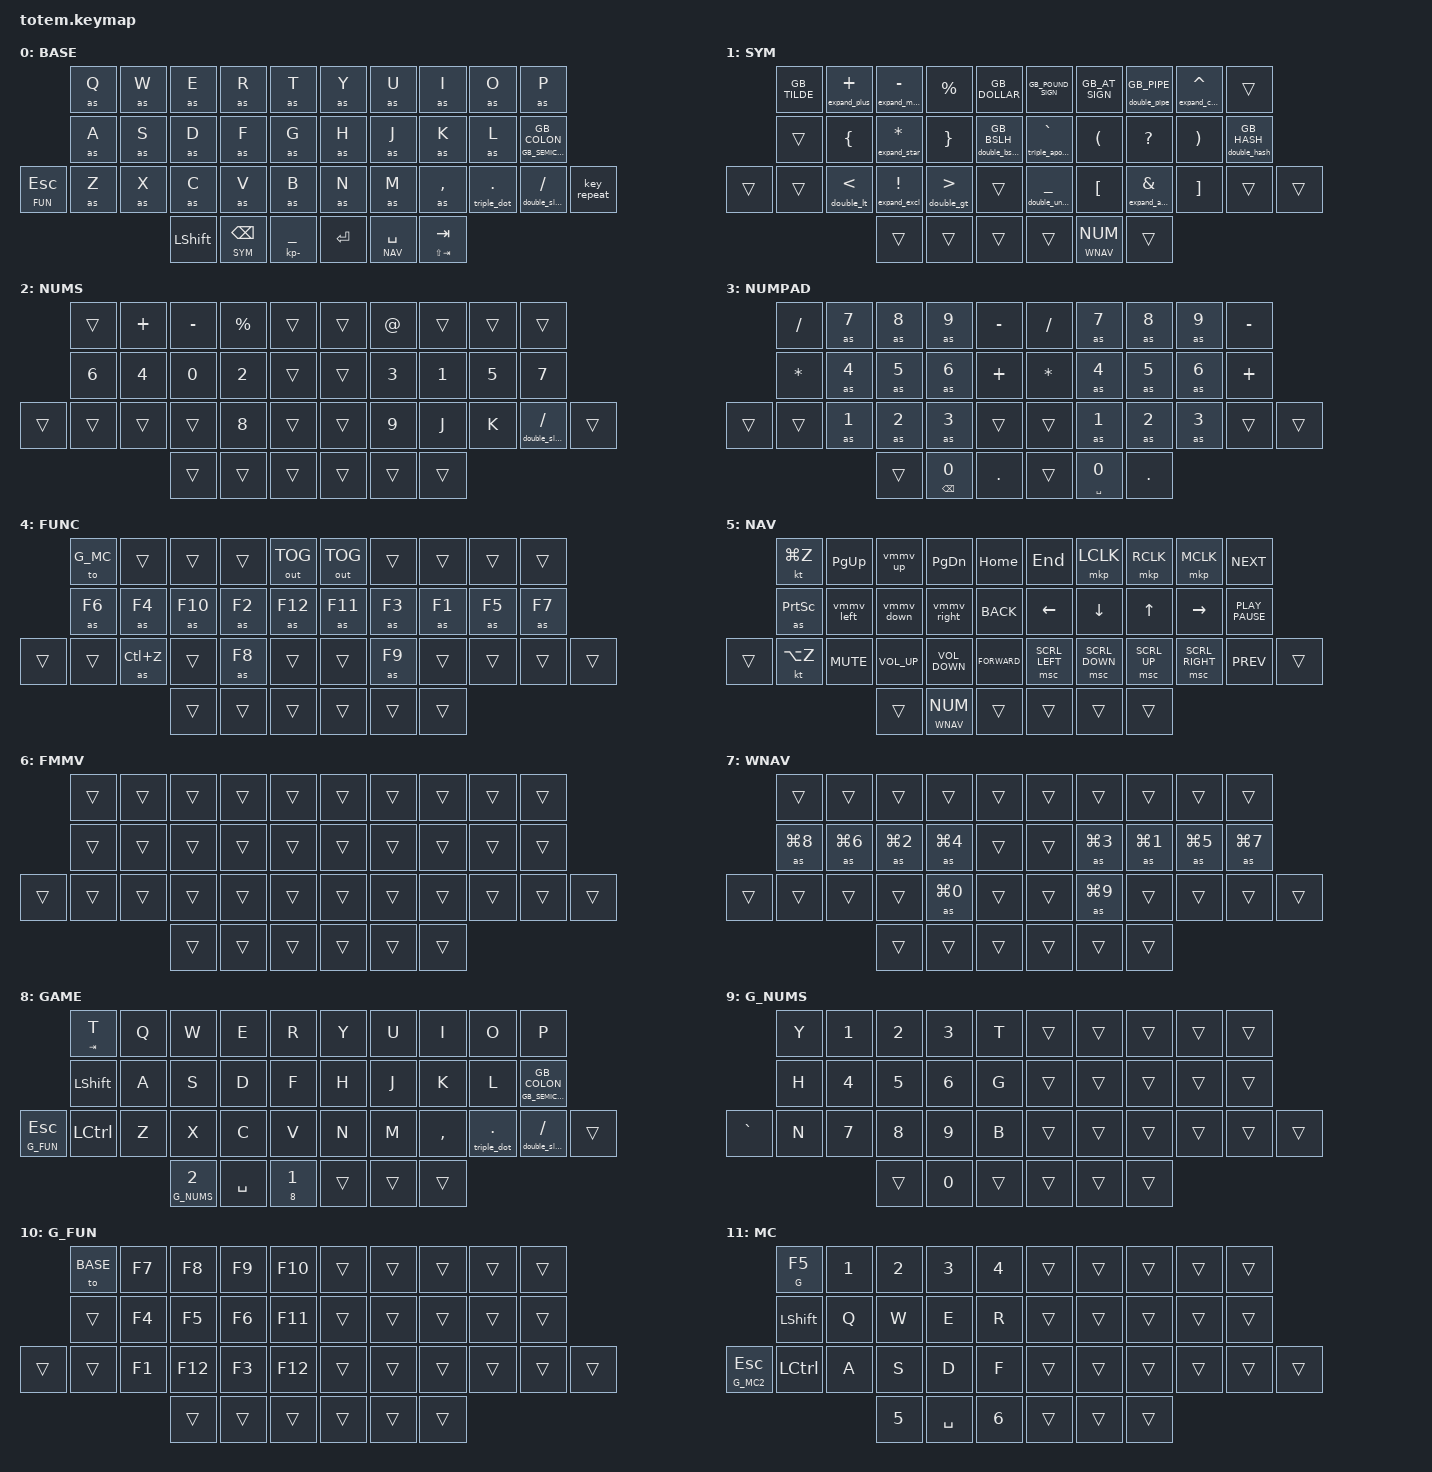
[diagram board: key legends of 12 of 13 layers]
//
//                                                        ▀▀▀▀▀     ▀▀▀▀▀          ▀▀█▀▀
//                                                        ▄▀▀▀▄  ▄  ▄▀▀▀▄  ▄  ▄▀▀▀▄  █  ▄▀▀▀▄
//                                                        █   █  █  █   █  █  █   █  █  █   █
//                                                         ▀▀▀   █   ▀▀▀   █   ▀▀▀   ▀   ▀▀▀
//                                                               █      ▄▄▄█▄▄▄    █   █
//                                                               ▀      █  █  █     █▄█
//                                                             ▀▀▀▀▀    █  █  █      ▀
//                                                                      ▀  ▀  ▀
//
// ▄▄▄▄▄▄▄▄▄▄▄▄▄▄▄▄▄▄▄▄▄▄▄▄▄▄▄▄▄▄▄▄▄▄▄▄▄▄▄▄▄▄▄▄▄▄▄▄▄▄▄▄▄▄▄▄▄▄▄▄▄▄▄▄▄▄▄▄▄▄▄▄▄▄▄▄▄▄▄▄▄▄▄▄▄▄▄▄▄▄▄▄▄▄▄▄▄▄▄▄▄▄▄▄▄▄▄▄▄▄▄▄▄▄▄▄▄▄▄▄▄▄▄▄▄▄▄▄▄▄▄▄▄▄▄▄▄▄▄▄▄▄▄▄▄▄▄▄▄

#include <behaviors/num_word.dtsi>
#include "keys_en_gb.h"
#include <input/processors.dtsi>
#include <zephyr/dt-bindings/input/input-event-codes.h>
#include <behaviors.dtsi>
#include <dt-bindings/zmk/bt.h>
#include <dt-bindings/zmk/keys.h>
#include <dt-bindings/zmk/outputs.h>
#include <dt-bindings/zmk/pointing.h>

#define BASE 0
#define SYM 1
#define NUM 2
#define NUMPAD 3
#define FUN 4
#define NAV 5
#define FMMV 6
#define WNAV 7
#define GAME 8
#define G_NUMS 9
#define G_FUN 10
#define G_MC 11
#define G_MC2 12
#define COMBO_LAYERS <BASE SYM NUM NUMPAD FUN NAV FMMV WNAV GAME>


&mt {
    quick-tap-ms = <100>;
    global-quick-tap;
    flavor = "tap-preferred";
    tapping-term-ms = <170>;
};

&num_word {
    continue-list = <
    BSPC DEL
    DOT COMMA
    PLUS MINUS STAR FSLH EQUAL
    // J K AT_SIGN V G LS(G)
    >;
};

&mmv_input_listener {
    fast {
        layers = <FMMV>;
        input-processors = <&zip_xy_scaler 2 1>;
    };
};

/ {
    combos {
        //     0   1   2   3   4   5   6   7   8   9
        //     10  11  12  13  14  15  16  17  18  19
        // 20  21  22  23  24  25  26  27  28  29  30  31
        //             32  33  34  35  36  37

        compatible = "zmk,combos";

        combo_z {
            bindings = <&kp Z>;
            key-positions = <21 22>;
            layers = COMBO_LAYERS;
        };

        combo_dollar {
            bindings = <&kp DOLLAR>;
            key-positions = <28 29>;
            layers = COMBO_LAYERS;
        };

        combo_speech {
            bindings = <&HT_Triple_Speech 0 GB_DQT>;
            key-positions = <11 13>;
            layers = COMBO_LAYERS;
        };

        combo_quotes {
            bindings = <&HT_Triple_Quotes 0 SQT>;
            key-positions = <16 18>;
            layers = COMBO_LAYERS;
        };

        combo_eq {
            bindings = <&HT_Double_Equal 0 EQUAL>;
            key-positions = <6 7>;
            layers = COMBO_LAYERS;
        };

        combo_del {
            bindings = <&kp DEL>;
            key-positions = <13 14>;
            layers = COMBO_LAYERS;
        };

        combo_ctrl_del {
            bindings = <&kp LC(DELETE)>;
            key-positions = <1 2 3>;
            layers = COMBO_LAYERS;
        };

        combo_ctrl_w_r {
            bindings = <&kp LC(W)>;
            key-positions = <7 6 8>;
            layers = COMBO_LAYERS;
        };

        combo_backspace_word {
            bindings = <&kp LC(BSPC)>;
            key-positions = <8 9>;
            layers = COMBO_LAYERS;
        };

        combo_tab {
            bindings = <&mt LS(TAB) TAB>;
            key-positions = <11 12 13>;
            layers = COMBO_LAYERS;
        };

        combo_ctrl_r {
            bindings = <&sk LCTRL>;
            key-positions = <17 18>;
            layers = COMBO_LAYERS;
        };

        combo_ctrl_l {
            bindings = <&sk LCTRL>;
            key-positions = <11 12>;
            layers = COMBO_LAYERS;
        };

        combo_super_l {
            bindings = <&sk LGUI>;
            key-positions = <23 24>;
            layers = COMBO_LAYERS;
        };

        combo_super_r {
            bindings = <&sk LGUI>;
            key-positions = <27 28>;
            layers = COMBO_LAYERS;
        };

        combo_alt_l {
            bindings = <&sk LEFT_ALT>;
            key-positions = <12 13>;
            layers = COMBO_LAYERS;
        };

        combo_alt_r {
            bindings = <&sk LEFT_ALT>;
            key-positions = <16 17>;
            layers = COMBO_LAYERS;
        };

        combo_shift_l {
            bindings = <&sk LEFT_SHIFT>;
            key-positions = <24 25>;
            layers = COMBO_LAYERS;
        };

        combo_shift_r {
            bindings = <&sk LEFT_SHIFT>;
            key-positions = <26 27>;
            layers = COMBO_LAYERS;
        };

        combo_leq {
            bindings = <&leq>;
            key-positions = <3 13>;
            layers = COMBO_LAYERS;
        };

        combo_geq1 {
            bindings = <&geq1>;
            key-positions = <13 24>;
            layers = COMBO_LAYERS;
        };

        combo_geq2 {
            bindings = <&geq2>;
            key-positions = <6 16>;
            layers = COMBO_LAYERS;
        };

        combo_from {
            bindings = <&from>;
            key-positions = <2 12>;
            layers = COMBO_LAYERS;
        };

        combo_to {
            bindings = <&combo_to>;
            key-positions = <7 17>;
            layers = COMBO_LAYERS;
        };

        combo_hsplit {
            bindings = <&hsplit>;
            key-positions = <11 22>;
            layers = COMBO_LAYERS;
        };

        combo_vsplit {
            bindings = <&vsplit>;
            key-positions = <22 23>;
            layers = COMBO_LAYERS;
        };

        combo_write {
            bindings = <&write>;
            key-positions = <16 17 18>;
            layers = COMBO_LAYERS;
        };

        combo_close_window {
            bindings = <&quit>;
            key-positions = <22 23 24>;
            layers = COMBO_LAYERS;
        };

        combo_numword {
            bindings = <&numword_tapdance>;
            key-positions = <36 33>;
            layers = COMBO_LAYERS;
        };

        combo_capsword {
            bindings = <&caps_word>;
            key-positions = <12 17>;
            layers = COMBO_LAYERS;
        };

        combo_game_layer {
            bindings = <&tog GAME>;
            key-positions = <0 21 30 9>;
        };

        combo_numpad_left {
            bindings = <&tog NUMPAD>;
            key-positions = <33 34>;
            layers = COMBO_LAYERS;
        };

        combo_flash_dongle {
            bindings = <&bootloader>;
            key-positions = <0 25 26 9>;
            layers = COMBO_LAYERS;
        };

        bt {
            bindings = <&bt BT_CLR_ALL>;
            key-positions = <22 23 24 25 26 27 28 29>;
            layers = COMBO_LAYERS;
        };

        bt_prev {
            bindings = <&bt BT_PRV>;
            key-positions = <22 23 24 25>;
            layers = COMBO_LAYERS;
        };

        bt_next {
            bindings = <&bt BT_NXT>;
            key-positions = <26 27 28 29>;
            layers = COMBO_LAYERS;
        };

        combo_l_sym_0 {
            bindings = <&kp GB_TILDE>;
            key-positions = <33 0>;
            layers = COMBO_LAYERS;
        };

        combo_l_sym_1 {
            bindings = <&HT_Expand_Plus 0 PLUS>;
            key-positions = <33 1>;
            layers = COMBO_LAYERS;
        };

        combo_l_sym_2 {
            bindings = <&HT_Expand_Minus 0 MINUS>;
            key-positions = <33 2>;
            layers = COMBO_LAYERS;
        };

        combo_l_sym_3 {
            bindings = <&kp PERCENT>;
            key-positions = <33 3>;
            layers = COMBO_LAYERS;
        };

        combo_l_sym_4 {
            bindings = <&kp GB_DOLLAR>;
            key-positions = <33 4>;
            layers = COMBO_LAYERS;
        };

        combo_l_sym_11 {
            bindings = <&kp LBRC>;
            key-positions = <33 11>;
            layers = COMBO_LAYERS;
        };

        combo_l_sym_12 {
            bindings = <&HT_Expand_Star 0 STAR>;
            key-positions = <33 12>;
            layers = COMBO_LAYERS;
        };

        combo_l_sym_13 {
            bindings = <&kp RBRC>;
            key-positions = <33 13>;
            layers = COMBO_LAYERS;
        };

        combo_l_sym_14 {
            bindings = <&HT_Double_Bslash 0 GB_BSLH>;
            key-positions = <33 14>;
            layers = COMBO_LAYERS;
        };

        combo_l_sym_22 {
            bindings = <&HT_Double_LT 0 LT>;
            key-positions = <33 22>;
            layers = COMBO_LAYERS;
        };

        combo_l_sym_23 {
            bindings = <&HT_Expand_Bang 0 EXCL>;
            key-positions = <33 23>;
            layers = COMBO_LAYERS;
        };

        combo_l_sym_24 {
            bindings = <&HT_Double_GT 0 GT>;
            key-positions = <33 24>;
            layers = COMBO_LAYERS;
        };

        combo_l_num_1 {
            bindings = <&kp PLUS>;
            key-positions = <36 1>;
            layers = COMBO_LAYERS;
        };

        combo_l_num_2 {
            bindings = <&kp MINUS>;
            key-positions = <36 2>;
            layers = COMBO_LAYERS;
        };

        combo_l_num_3 {
            bindings = <&kp PERCENT>;
            key-positions = <36 3>;
            layers = COMBO_LAYERS;
        };

        combo_l_num_10 {
            bindings = <&kp N6>;
            key-positions = <36 10>;
            layers = COMBO_LAYERS;
        };

        combo_l_num_11 {
            bindings = <&kp N4>;
            key-positions = <36 11>;
            layers = COMBO_LAYERS;
        };

        combo_l_num_12 {
            bindings = <&kp N0>;
            key-positions = <36 12>;
            layers = COMBO_LAYERS;
        };

        combo_l_num_13 {
            bindings = <&kp N2>;
            key-positions = <36 13>;
            layers = COMBO_LAYERS;
        };

        combo_l_num_24 {
            bindings = <&kp N8>;
            key-positions = <36 24>;
            layers = COMBO_LAYERS;
        };

        combo_r_sym_5 {
            bindings = <&kp GB_POUND_SIGN>;
            key-positions = <36 5>;
            layers = COMBO_LAYERS;
        };

        combo_r_sym_6 {
            bindings = <&kp GB_AT_SIGN>;
            key-positions = <36 6>;
            layers = COMBO_LAYERS;
        };

        combo_r_sym_7 {
            bindings = <&HT_Double_Pipe 0 GB_PIPE>;
            key-positions = <36 7>;
            layers = COMBO_LAYERS;
        };

        combo_r_sym_8 {
            bindings = <&HT_Expand_Caret 0 CARET>;
            key-positions = <36 8>;
            layers = COMBO_LAYERS;
        };

        combo_r_sym_15 {
            bindings = <&HT_Triple_Apostrophe 0 GRAVE>;
            key-positions = <36 15>;
            layers = COMBO_LAYERS;
        };

        combo_r_sym_16 {
            bindings = <&kp LPAR>;
            key-positions = <36 16>;
            layers = COMBO_LAYERS;
        };

        combo_r_sym_17 {
            bindings = <&kp QMARK>;
            key-positions = <36 17>;
            layers = COMBO_LAYERS;
        };

        combo_r_sym_18 {
            bindings = <&kp RPAR>;
            key-positions = <36 18>;
            layers = COMBO_LAYERS;
        };

        combo_r_sym_19 {
            bindings = <&HT_Double_Hash 0 GB_HASH>;
            key-positions = <36 19>;
            layers = COMBO_LAYERS;
        };

        combo_r_sym_26 {
            bindings = <&HT_Double_Underscore 0 UNDERSCORE>;
            key-positions = <36 26>;
            layers = COMBO_LAYERS;
        };

        combo_r_sym_27 {
            bindings = <&kp LBKT>;
            key-positions = <36 27>;
            layers = COMBO_LAYERS;
        };

        combo_r_sym_28 {
            bindings = <&HT_Expand_Amps 0 AMPS>;
            key-positions = <36 28>;
            layers = COMBO_LAYERS;
        };

        combo_r_sym_29 {
            bindings = <&kp RBKT>;
            key-positions = <36 29>;
            layers = COMBO_LAYERS;
        };

        combo_r_num_6 {
            bindings = <&kp AT>;
            key-positions = <33 6>;
            layers = COMBO_LAYERS;
        };

        combo_r_num_16 {
            bindings = <&kp N3>;
            key-positions = <33 16>;
            layers = COMBO_LAYERS;
        };

        combo_r_num_17 {
            bindings = <&kp N1>;
            key-positions = <33 17>;
            layers = COMBO_LAYERS;
        };

        combo_r_num_18 {
            bindings = <&kp N5>;
            key-positions = <33 18>;
            layers = COMBO_LAYERS;
        };

        combo_r_num_19 {
            bindings = <&kp N7>;
            key-positions = <33 19>;
            layers = COMBO_LAYERS;
        };

        combo_r_num_27 {
            bindings = <&kp N9>;
            key-positions = <33 27>;
            layers = COMBO_LAYERS;
        };

        combo_r_num_28 {
            bindings = <&kp J>;
            key-positions = <33 28>;
            layers = COMBO_LAYERS;
        };

        combo_r_num_29 {
            bindings = <&kp K>;
            key-positions = <33 29>;
            layers = COMBO_LAYERS;
        };

        combo_r_num_30 {
            bindings = <&HT_Double_Slash 0 SLASH>;
            key-positions = <33 30>;
            layers = COMBO_LAYERS;
        };
    };

    macros {
        from: from {
            compatible = "zmk,behavior-macro";
            #binding-cells = <0>;
            bindings = <&kp SPACE &kp LT &kp MINUS &kp SPACE>;
        };

        combo_to: to {
            compatible = "zmk,behavior-macro";
            #binding-cells = <0>;
            bindings = <&none &kp SPACE &kp MINUS &kp GT &kp SPACE>;
        };

        geq1: geq1 {
            compatible = "zmk,behavior-macro";
            #binding-cells = <0>;
            bindings = <&none &kp SPACE &kp GT &kp EQUAL &kp SPACE>;
        };

        geq2: geq2 {
            compatible = "zmk,behavior-macro";
            #binding-cells = <0>;
            bindings = <&none &kp SPACE &kp EQUAL &kp GT &kp SPACE>;
        };

        leq: leq {
            compatible = "zmk,behavior-macro";
            #binding-cells = <0>;
            bindings = <&none &kp SPACE &kp LT &kp EQUAL &kp SPACE>;
        };

        write: write {
            compatible = "zmk,behavior-macro";
            #binding-cells = <0>;
            bindings = <&kp ESCAPE &kp GB_COLON &kp W &kp ENTER>;
        };

        quit: quit {
            compatible = "zmk,behavior-macro";
            #binding-cells = <0>;
            bindings = <&kp ESCAPE &kp GB_COLON &kp Q &kp ENTER>;
        };

        hsplit: hsplit {
            compatible = "zmk,behavior-macro";
            #binding-cells = <0>;
            bindings = <&kp LC(W) &kp S>;
        };

        vsplit: vsplit {
            compatible = "zmk,behavior-macro";
            #binding-cells = <0>;
            bindings = <&kp LC(W) &kp V>;
        };

        expand_amps: expand_amps {
            compatible = "zmk,behavior-macro";
            #binding-cells = <0>;
            bindings = <&kp SPACE &kp AMPS &kp EQUAL &kp SPACE>;
        };

        expand_caret: expand_caret {
            compatible = "zmk,behavior-macro";
            #binding-cells = <0>;
            bindings = <&kp SPACE &kp CARET &kp EQUAL &kp SPACE>;
        };

        expand_plus: expand_plus {
            compatible = "zmk,behavior-macro";
            #binding-cells = <0>;
            bindings = <&kp SPACE &kp PLUS &kp EQUAL &kp SPACE>;
        };

        expand_minus: expand_minus {
            compatible = "zmk,behavior-macro";
            #binding-cells = <0>;
            bindings = <&kp SPACE &kp MINUS &kp EQUAL &kp SPACE>;
        };

        expand_star: expand_star {
            compatible = "zmk,behavior-macro";
            #binding-cells = <0>;
            bindings = <&kp SPACE &kp STAR &kp EQUAL &kp SPACE>;
        };

        expand_excl: expand_excl {
            compatible = "zmk,behavior-macro";
            #binding-cells = <0>;
            bindings = <&kp SPACE &kp EXCL &kp EQUAL &kp SPACE>;
        };

        double_underscore: double_underscore {
            compatible = "zmk,behavior-macro";
            #binding-cells = <0>;
            bindings = <&kp UNDER &kp UNDER>;
        };

        double_lt: double_lt {
            compatible = "zmk,behavior-macro";
            #binding-cells = <0>;
            bindings = <&kp LT &kp LT>;
        };

        double_gt: double_gt {
            compatible = "zmk,behavior-macro";
            #binding-cells = <0>;
            bindings = <&kp GT &kp GT>;
        };

        double_slash: double_slash {
            compatible = "zmk,behavior-macro";
            #binding-cells = <0>;
            bindings = <&kp SLASH &kp SLASH>;
        };

        double_bslash: double_bslash {
            compatible = "zmk,behavior-macro";
            #binding-cells = <0>;
            bindings = <&kp GB_BSLH &kp GB_BSLH>;
        };

        double_hash: double_hash {
            compatible = "zmk,behavior-macro";
            #binding-cells = <0>;
            bindings = <&kp GB_HASH &kp GB_HASH>;
        };

        triple_speech: triple_speech {
            compatible = "zmk,behavior-macro";
            #binding-cells = <0>;
            bindings = <&kp GB_DQT &kp GB_DQT &kp GB_DQT>;
        };

        triple_quotes: triple_quotes {
            compatible = "zmk,behavior-macro";
            #binding-cells = <0>;
            bindings = <&kp SQT &kp SQT &kp SQT>;
        };

        triple_eq: triple_eq {
            compatible = "zmk,behavior-macro";
            #binding-cells = <0>;
            bindings = <&kp EQUAL &kp EQUAL &kp EQUAL>;
        };

        triple_zero: triple_zero {
            compatible = "zmk,behavior-macro";
            #binding-cells = <0>;
            bindings = <&kp N0 &kp N0 &kp N0>;
        };

        triple_dot: triple_dot {
            compatible = "zmk,behavior-macro";
            #binding-cells = <0>;
            bindings = <&kp DOT &kp DOT &kp DOT>;
        };

        double_pipe: double_pipe {
            compatible = "zmk,behavior-macro";
            #binding-cells = <0>;
            bindings = <&kp SPACE &kp GB_PIPE &kp GB_PIPE &kp SPACE>;
        };

        double_equal: double_equal {
            compatible = "zmk,behavior-macro";
            #binding-cells = <0>;
            bindings = <&kp SPACE &kp EQUAL &kp EQUAL &kp SPACE>;
        };

        double_amp: double_amp {
            compatible = "zmk,behavior-macro";
            #binding-cells = <0>;
            bindings = <&kp SPACE &kp AMPS &kp AMPS &kp SPACE>;
        };

        triple_apostrophe: triple_apostrophe {
            compatible = "zmk,behavior-macro";
            #binding-cells = <0>;
            bindings = <&kp GRAVE &kp GRAVE &kp GRAVE>;
        };

        as: autoshift {
            compatible = "zmk,behavior-macro-one-param";
            #binding-cells = <1>;
            bindings =
                <&macro_press>,
                <&macro_param_1to1 &macro_param_1to2 &as_ht MACRO_PLACEHOLDER MACRO_PLACEHOLDER>,
                <&macro_pause_for_release>,
                <&macro_release>,
                <&macro_param_1to1 &macro_param_1to2 &as_ht MACRO_PLACEHOLDER MACRO_PLACEHOLDER>;
        };

        shifted: macro_shifted_kp {
            #binding-cells = <1>;
            compatible = "zmk,behavior-macro-one-param";
            bindings =
                <&macro_press>,
                <&kp LSHFT &macro_param_1to1>,
                <&macro_tap>,
                <&kp MACRO_PLACEHOLDER>,
                <&macro_release>,
                <&kp LSHFT>;
        };

        double_speech: double_speech {
            compatible = "zmk,behavior-macro";
            #binding-cells = <0>;
            bindings = <&kp GB_DQT &kp GB_DQT>;
        };

        double_quotes: double_quotes {
            compatible = "zmk,behavior-macro";
            #binding-cells = <0>;
            bindings = <&kp SQT &kp SQT>;
        };
    };

    behaviors {
        // fmmv: fast_mouse_move {
        //     compatible = "zmk,behavior-input-two-axis";
        //     #binding-cells = <1>;
        //     x-input-code = <INPUT_REL_X>;
        //     y-input-code = <INPUT_REL_Y>;
        //     time-to-max-speed-ms = <150>;
        //     acceleration-exponent = <1>;
        // };
        long_mt: long_mod_tap {
            compatible = "zmk,behavior-hold-tap";
            #binding-cells = <2>;
            flavor = "hold-preferred";
            tapping-term-ms = <250>;
            bindings = <&kp>, <&kp>;
            display-name = "Long Mod-Tap";
        };

        vmmv_up: variable_mouse_move_up {
            compatible = "zmk,behavior-tap-dance";
            #binding-cells = <0>;
            tapping-term-ms = <200>;
            bindings = <&mmv MOVE_UP>, <&tog FMMV>;
        };

        vmmv_down: variable_mouse_move_down {
            compatible = "zmk,behavior-tap-dance";
            #binding-cells = <0>;
            tapping-term-ms = <200>;
            bindings = <&mmv MOVE_DOWN>, <&tog FMMV>;
        };

        vmmv_left: variable_mouse_move_left {
            compatible = "zmk,behavior-tap-dance";
            #binding-cells = <0>;
            tapping-term-ms = <200>;
            bindings = <&mmv MOVE_LEFT>, <&tog FMMV>;
        };

        vmmv_right: variable_mouse_move_right {
            compatible = "zmk,behavior-tap-dance";
            #binding-cells = <0>;
            tapping-term-ms = <200>;
            bindings = <&mmv MOVE_RIGHT>, <&tog FMMV>;
        };

        numword_holdtap: numword_holdtap {
            compatible = "zmk,behavior-hold-tap";
            flavor = "hold-preferred";
            #binding-cells = <2>;
            tapping-term-ms = <200>;
            bindings = <&mo>, <&num_word>;
        };

        numword_tapdance: numword_tapdance {
            compatible = "zmk,behavior-tap-dance";
            #binding-cells = <0>;
            bindings = <&numword_holdtap WNAV NUM>, <&tog NUM>;
        };

        colon_switch: colon_switch {
            compatible = "zmk,behavior-mod-morph";
            #binding-cells = <0>;
            bindings = <&kp COLON>, <&kp SEMICOLON>;

            mods = <(MOD_LSFT|MOD_RSFT)>;
        };

        HT_Expand_Amps: ht_expand_Amps {
            compatible = "zmk,behavior-hold-tap";
            flavor = "hold-preferred";
            #binding-cells = <2>;
            tapping-term-ms = <200>;
            bindings = <&expand_amps>, <&kp>;
        };

        HT_Expand_Caret: ht_expand_caret {
            compatible = "zmk,behavior-hold-tap";
            flavor = "hold-preferred";
            #binding-cells = <2>;
            tapping-term-ms = <200>;
            bindings = <&expand_caret>, <&kp>;
        };

        HT_Expand_Plus: ht_expand_plus {
            compatible = "zmk,behavior-hold-tap";
            flavor = "hold-preferred";
            #binding-cells = <2>;
            tapping-term-ms = <200>;
            bindings = <&expand_plus>, <&kp>;
        };

        HT_Expand_Minus: ht_expand_minus {
            compatible = "zmk,behavior-hold-tap";
            flavor = "hold-preferred";
            #binding-cells = <2>;
            tapping-term-ms = <200>;
            bindings = <&expand_minus>, <&kp>;
        };

        HT_Expand_Star: ht_expand_star {
            compatible = "zmk,behavior-hold-tap";
            flavor = "hold-preferred";
            #binding-cells = <2>;
            tapping-term-ms = <200>;
            bindings = <&expand_star>, <&kp>;
        };

        HT_Expand_Bang: ht_expand_bang {
            compatible = "zmk,behavior-hold-tap";
            flavor = "hold-preferred";
            #binding-cells = <2>;
            tapping-term-ms = <200>;
            bindings = <&expand_excl>, <&kp>;
        };

        HT_Double_Underscore: hold_tap_double_underscore {
            compatible = "zmk,behavior-hold-tap";
            flavor = "hold-preferred";
            #binding-cells = <2>;
            tapping-term-ms = <200>;
            bindings = <&double_underscore>, <&kp>;
        };

        HT_Double_LT: ht_double_LT {
            compatible = "zmk,behavior-hold-tap";
            flavor = "hold-preferred";
            #binding-cells = <2>;
            tapping-term-ms = <200>;
            bindings = <&double_lt>, <&kp>;
        };

        HT_Double_GT: ht_double_GT {
            compatible = "zmk,behavior-hold-tap";
            flavor = "hold-preferred";
            #binding-cells = <2>;
            tapping-term-ms = <200>;
            bindings = <&double_gt>, <&kp>;
        };

        HT_Double_Slash: ht_double_slash {
            compatible = "zmk,behavior-hold-tap";
            flavor = "hold-preferred";
            #binding-cells = <2>;
            tapping-term-ms = <200>;
            bindings = <&double_slash>, <&kp>;
        };

        HT_Double_Bslash: ht_double_bslash {
            compatible = "zmk,behavior-hold-tap";
            flavor = "hold-preferred";
            #binding-cells = <2>;
            tapping-term-ms = <200>;
            bindings = <&double_bslash>, <&kp>;
        };

        HT_Double_Hash: ht_double_hash {
            compatible = "zmk,behavior-hold-tap";
            flavor = "hold-preferred";
            #binding-cells = <2>;
            tapping-term-ms = <200>;
            bindings = <&double_hash>, <&kp>;
        };

        HT_Triple_Speech: ht_triple_speech {
            compatible = "zmk,behavior-hold-tap";
            flavor = "hold-preferred";
            #binding-cells = <2>;
            tapping-term-ms = <200>;
            bindings = <&triple_speech>, <&kp>;
        };

        HT_Triple_Quotes: ht_triple_quotes {
            compatible = "zmk,behavior-hold-tap";
            flavor = "hold-preferred";
            #binding-cells = <2>;
            tapping-term-ms = <200>;
            bindings = <&triple_quotes>, <&kp>;
        };

        HT_Triple_Eq: ht_triple_eq {
            compatible = "zmk,behavior-hold-tap";
            flavor = "hold-preferred";
            #binding-cells = <2>;
            tapping-term-ms = <200>;
            bindings = <&triple_eq>, <&kp>;
        };

        HT_Triple_Zero: ht_triple_zero {
            compatible = "zmk,behavior-hold-tap";
            flavor = "hold-preferred";
            #binding-cells = <2>;
            tapping-term-ms = <200>;
            bindings = <&triple_zero>, <&kp>;
        };

        HT_Triple_Dot: ht_triple_dot {
            compatible = "zmk,behavior-hold-tap";
            flavor = "hold-preferred";
            #binding-cells = <2>;
            tapping-term-ms = <200>;
            bindings = <&triple_dot>, <&kp>;
        };

        HT_Double_Pipe: ht_double_pipe {
            compatible = "zmk,behavior-hold-tap";
            flavor = "hold-preferred";
            #binding-cells = <2>;
            tapping-term-ms = <200>;
            bindings = <&double_pipe>, <&kp>;
        };

        HT_Double_Equal: ht_double_equal {
            compatible = "zmk,behavior-hold-tap";
            flavor = "hold-preferred";
            #binding-cells = <2>;
            tapping-term-ms = <200>;
            bindings = <&double_equal>, <&kp>;
        };

        HT_Double_Amps: ht_double_amps {
            compatible = "zmk,behavior-hold-tap";
            flavor = "hold-preferred";
            #binding-cells = <2>;
            tapping-term-ms = <200>;
            bindings = <&double_amp>, <&kp>;
        };

        HT_Triple_Apostrophe: ht_triple_apostrophe {
            compatible = "zmk,behavior-hold-tap";
            flavor = "hold-preferred";
            #binding-cells = <2>;
            tapping-term-ms = <200>;
            bindings = <&triple_apostrophe>, <&kp>;
        };

        as_ht: autoshift_hold_tap {
            compatible = "zmk,behavior-hold-tap";
            bindings = <&shifted>, <&kp>;

            flavor = "tap-preferred";
            quick-tap-ms = <150>;
            #binding-cells = <2>;
            tapping-term-ms = <250>;
        };

        colon_switch_2: colon_switch_2 {
            compatible = "zmk,behavior-hold-tap";
            bindings = <&kp>, <&kp>;

            #binding-cells = <2>;
            tapping-term-ms = <200>;
        };
    };

    // fmmv_input_listener: fmmv_input_listener {
    //     compatible = "zmk,input-listener";
    //     device = <&fmmv>;
    // };

    keymap {
        compatible = "zmk,keymap";

        base_layer {
            display-name = "BASE";
            bindings = <
                &as Q  &as W  &as E       &as R              &as T                      &as Y        &as U          &as I            &as O                 &as P
                &as A  &as S  &as D       &as F              &as G                      &as H        &as J          &as K            &as L                 &mt GB_SEMICOLON GB_COLON
&lt FUN ESCAPE  &as Z  &as X  &as C       &as V              &as B                      &as N        &as M          &as COMMA        &HT_Triple_Dot 0 DOT  &HT_Double_Slash 0 SLASH   &key_repeat
                              &kp LSHIFT  &lt SYM BACKSPACE  &mt KP_MINUS UNDERSCORE    &kp ENTER    &lt NAV SPACE  &mt LS(TAB) TAB
            >;
        };

        sym_layer {
            display-name = "SYM";
            bindings = <
        &kp GB_TILDE  &HT_Expand_Plus 0 PLUS  &HT_Expand_Minus 0 MINUS  &kp PERCENT         &kp GB_DOLLAR                  &kp GB_POUND_SIGN                   &kp GB_AT_SIGN             &HT_Double_Pipe 0 GB_PIPE  &HT_Expand_Caret 0 CARET  &trans
        &trans        &kp LBRC                &HT_Expand_Star 0 STAR    &kp RBRC            &HT_Double_Bslash 0 GB_BSLH    &HT_Triple_Apostrophe 0 GRAVE       &kp LPAR                   &kp QMARK                  &kp RPAR                  &HT_Double_Hash 0 GB_HASH
&trans  &trans        &HT_Double_LT 0 LT      &HT_Expand_Bang 0 EXCL    &HT_Double_GT 0 GT  &trans                         &HT_Double_Underscore 0 UNDERSCORE  &kp LBKT                   &HT_Expand_Amps 0 AMPS     &kp RBKT                  &trans                     &trans
                                              &trans                    &trans              &trans                         &trans                              &numword_holdtap WNAV NUM  &trans
            >;
        };

        number_layer {
            display-name = "NUMS";
            bindings = <
        &trans  &kp PLUS  &kp MINUS  &kp PERCENT  &trans    &trans  &kp AT  &trans  &trans  &trans
        &kp N6  &kp N4    &kp N0     &kp N2       &trans    &trans  &kp N3  &kp N1  &kp N5  &kp N7
&trans  &trans  &trans    &trans     &kp N8       &trans    &trans  &kp N9  &kp J   &kp K   &HT_Double_Slash 0 SLASH  &trans
                          &trans     &trans       &trans    &trans  &trans  &trans
            >;
        };

        numpad_layer {
            display-name = "NUMPAD";
            bindings = <
        &kp SLASH  &as N7  &as N8  &as N9            &kp MINUS    &kp SLASH  &as N7        &as N8   &as N9  &kp MINUS
        &kp STAR   &as N4  &as N5  &as N6            &kp PLUS     &kp STAR   &as N4        &as N5   &as N6  &kp PLUS
&trans  &trans     &as N1  &as N2  &as N3            &trans       &trans     &as N1        &as N2   &as N3  &trans     &trans
                           &trans  &mt BACKSPACE N0  &kp DOT      &trans     &mt SPACE N0  &kp DOT
            >;
        };

        fun_layer {
            display-name = "FUNC";
            bindings = <
        &to G_MC   &trans     &trans   &trans  &out OUT_TOG    &out OUT_TOG  &trans  &trans  &trans  &trans
        &as F6     &as F4     &as F10  &as F2  &as F12         &as F11       &as F3  &as F1  &as F5  &as F7
&trans  &trans     &as LC(Z)  &trans   &as F8  &trans          &trans        &as F9  &trans  &trans  &trans  &trans
                              &trans   &trans  &trans          &trans        &trans  &trans
            >;
        };

        nav_layer {
            display-name = "NAV";
            bindings = <
        &kt LG(Z)        &kp PG_UP   &vmmv_up         &kp PG_DN                  &kp HOME         &kp END         &mkp LCLK       &mkp RCLK     &mkp MCLK        &kp K_NEXT
        &as PRINTSCREEN  &vmmv_left  &vmmv_down       &vmmv_right                &kp K_BACK       &kp LEFT        &kp DOWN        &kp UP        &kp RIGHT        &kp K_PLAY_PAUSE
&trans  &kt LA(Z)        &kp K_MUTE  &kp K_VOLUME_UP  &kp K_VOLUME_DOWN          &kp K_FORWARD    &msc SCRL_LEFT  &msc SCRL_DOWN  &msc SCRL_UP  &msc SCRL_RIGHT  &kp K_PREV        &trans
                                     &trans           &numword_holdtap WNAV NUM  &trans           &trans          &trans          &trans
            >;
        };

        fmmv_layer {
            display-name = "FMMV";
            bindings = <
        &trans  &trans  &trans  &trans  &trans    &trans  &trans  &trans  &trans  &trans
        &trans  &trans  &trans  &trans  &trans    &trans  &trans  &trans  &trans  &trans
&trans  &trans  &trans  &trans  &trans  &trans    &trans  &trans  &trans  &trans  &trans  &trans
                        &trans  &trans  &trans    &trans  &trans  &trans
            >;
        };

        wnav_layer {
            display-name = "WNAV";
            bindings = <
        &trans      &trans      &trans      &trans      &trans    &trans  &trans      &trans      &trans      &trans
        &as LG(N8)  &as LG(N6)  &as LG(N2)  &as LG(N4)  &trans    &trans  &as LG(N3)  &as LG(N1)  &as LG(N5)  &as LG(N7)
&trans  &trans      &trans      &trans      &as LG(N0)  &trans    &trans  &as LG(N9)  &trans      &trans      &trans      &trans
                                &trans      &trans      &trans    &trans  &trans      &trans
            >;
        };

        game_layer {
            display-name = "GAME";
            bindings = <
                  &mt TAB T  &kp Q  &kp W          &kp E      &kp R       &kp Y        &kp U          &kp I            &kp O                 &kp P
                  &kp LSHFT  &kp A  &kp S          &kp D      &kp F       &kp H        &kp J          &kp K            &kp L                 &mt GB_SEMICOLON GB_COLON
&lt G_FUN ESCAPE  &kp LCTRL  &kp Z  &kp X          &kp C      &kp V       &kp N        &kp M          &kp COMMA        &HT_Triple_Dot 0 DOT  &HT_Double_Slash 0 SLASH   &trans
                                    &lt G_NUMS N2  &kp SPACE  &mt N8 N1   &trans  &trans  &trans
            >;
        };

        game_num_layer {
            display-name = "G_NUMS";
            bindings = <
           &kp Y  &kp N1  &kp N2  &kp N3  &kp T     &trans  &trans  &trans  &trans  &trans
           &kp H  &kp N4  &kp N5  &kp N6  &kp G     &trans  &trans  &trans  &trans  &trans
&kp GRAVE  &kp N  &kp N7  &kp N8  &kp N9  &kp B     &trans  &trans  &trans  &trans  &trans  &trans
                          &trans  &kp N0  &trans    &trans  &trans  &trans
            >;
        };

        game_fun_layer {
            bindings = <
        &to BASE   &kp F7  &kp F8   &kp F9  &kp F10    &trans  &trans  &trans  &trans  &trans
        &trans     &kp F4  &kp F5   &kp F6  &kp F11    &trans  &trans  &trans  &trans  &trans
&trans  &trans     &kp F1  &kp F12  &kp F3  &kp F12    &trans  &trans  &trans  &trans  &trans  &trans
                           &trans   &trans  &trans     &trans  &trans  &trans
            >;

            label = "G_FUN";
        };

        game_mc_layer {
            display-name = "MC";
            bindings = <
                  &mt G F5    &kp N1 &kp N2         &kp N3     &kp N4         &trans  &trans  &trans  &trans  &trans
                  &kp LSHFT   &kp Q  &kp W          &kp E      &kp R          &trans  &trans  &trans  &trans  &trans
&lt G_MC2 ESCAPE  &kp LCTRL   &kp A  &kp S          &kp D      &kp F          &trans  &trans  &trans  &trans  &trans  &trans
                                     &kp N5         &kp SPACE  &kp N6   &trans  &trans  &trans
            >;
        };

        game_mc_layer2 {
            display-name = "MC 2";
            bindings = <
        &to BASE &kp N1  &kp N2     &kp SQT     &kp F    &trans  &trans  &trans  &trans  &trans
        &kp N0   &kp V   &mkp MCLK  &kp LALT    &kp G    &trans  &trans  &trans  &trans  &trans
&trans  &kp TAB  &kp N   &kp LSHFT  &kp C       &kp B    &trans  &kp LT  &trans  &kp GT  &trans  &trans
                         &kp Y      &kp F4      &kp F3   &trans  &trans  &trans
            >;
        };
    };
};
